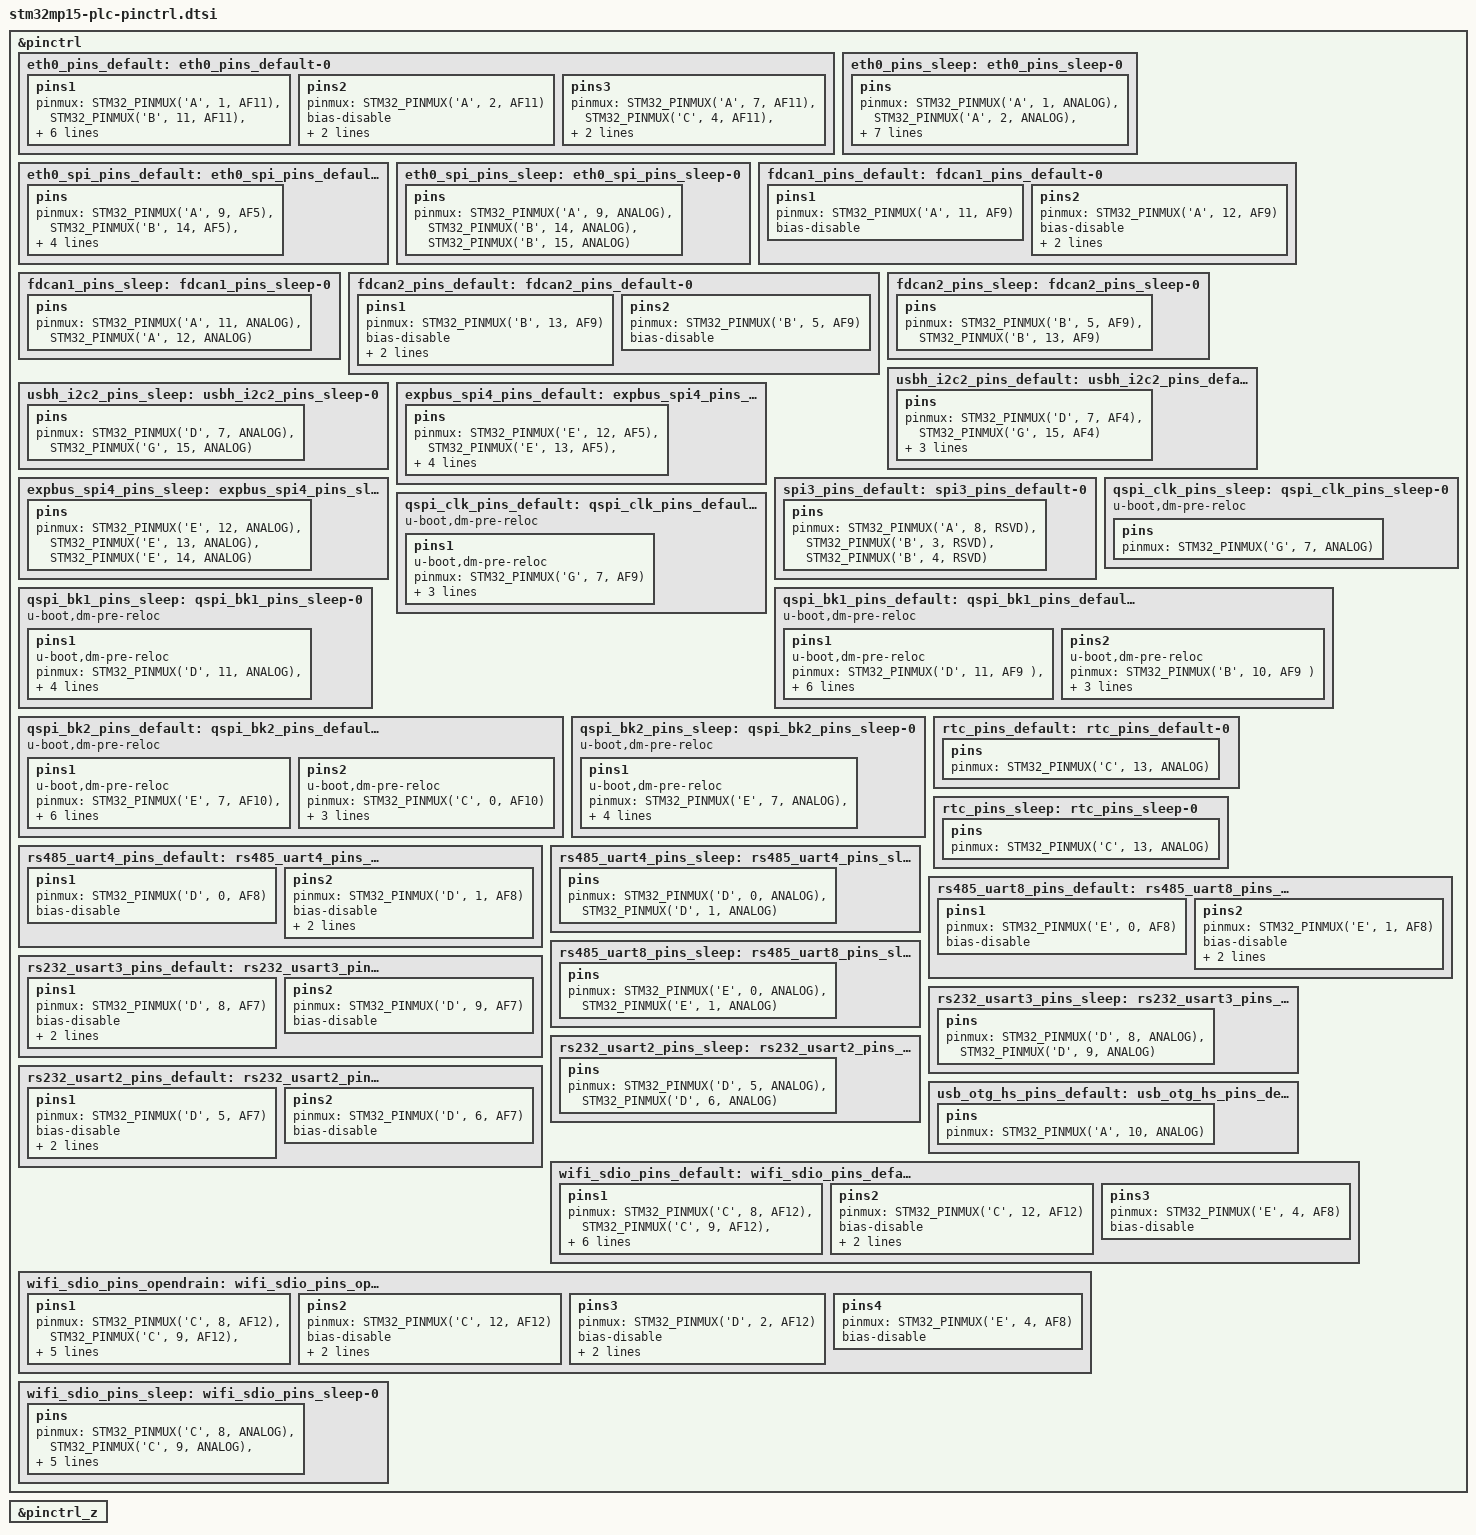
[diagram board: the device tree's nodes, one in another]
/* SPDX-License-Identifier: (GPL-2.0+ OR BSD-3-Clause) */
/*
 * Copyright (C) STMicroelectronics 2020 - All Rights Reserved
 * Author: STM32CubeMX code generation for STMicroelectronics.
 */

/* For more information on Device Tree configuration, please refer to
 * https://wiki.st.com/stm32mpu/wiki/Category:Device_tree_configuration
 */

#include <dt-bindings/pinctrl/stm32-pinfunc.h>

#include "stm32mp153.dtsi"
#include "stm32mp15xd.dtsi"
#include "stm32mp15xxab-pinctrl.dtsi"
#include "stm32mp15-m4-srm.dtsi"

&pinctrl {
/* PLC Ethernet interface pin configuration START */
	eth0_pins_default: eth0_pins_default-0 {		
		pins1 {
			pinmux = <STM32_PINMUX('A',  1, AF11)>, /* ETH1_REF_CLK */
					 <STM32_PINMUX('B', 11, AF11)>, /* ETH1_TX_EN   */
					 <STM32_PINMUX('C',  1, AF11)>, /* ETH1_MDC     */
					 <STM32_PINMUX('G', 13, AF11)>, /* ETH1_TXD0    */
					 <STM32_PINMUX('G', 14, AF11)>; /* ETH1_TXD1    */
			bias-disable;
			drive-push-pull;
			slew-rate = <1>;
		};
		pins2 {
			pinmux = <STM32_PINMUX('A',  2, AF11)>; /* ETH1_MDIO */
			bias-disable;
			drive-push-pull;
			slew-rate = <0>;
		};
		pins3 {
			pinmux = <STM32_PINMUX('A',  7, AF11)>, /* ETH1_CRS_DV */
					 <STM32_PINMUX('C',  4, AF11)>, /* ETH1_RXD0   */
					 <STM32_PINMUX('C',  5, AF11)>; /* ETH1_RXD1   */
			bias-disable;
		};
	};

	eth0_pins_sleep: eth0_pins_sleep-0 {
		pins {
			pinmux = <STM32_PINMUX('A',  1, ANALOG)>, /* ETH1_REF_CLK */
					 <STM32_PINMUX('A',  2, ANALOG)>, /* ETH1_MDIO    */
					 <STM32_PINMUX('A',  7, ANALOG)>, /* ETH1_CRS_DV  */
					 <STM32_PINMUX('B', 11, ANALOG)>, /* ETH1_TX_EN   */
					 <STM32_PINMUX('C',  1, ANALOG)>, /* ETH1_MDC     */
					 <STM32_PINMUX('C',  4, ANALOG)>, /* ETH1_RXD0    */
					 <STM32_PINMUX('C',  5, ANALOG)>, /* ETH1_RXD1    */
					 <STM32_PINMUX('G', 13, ANALOG)>, /* ETH1_TXD0    */
					 <STM32_PINMUX('G', 14, ANALOG)>; /* ETH1_TXD1    */
		};
	};

	eth0_spi_pins_default: eth0_spi_pins_default-0 {
		pins {
			pinmux = <STM32_PINMUX('A', 9, AF5)>,  /* SPI2_SCK */
					 <STM32_PINMUX('B', 14, AF5)>, /* SPI2_MISO */
					 <STM32_PINMUX('B', 15, AF5)>; /* SPI2_MOSI */
			bias-disable;
			drive-push-pull;
			slew-rate = <1>;
		};
	};
	
	eth0_spi_pins_sleep: eth0_spi_pins_sleep-0 {
		pins {
			pinmux = <STM32_PINMUX('A', 9, ANALOG)>,  /* SPI2_SCK */
					 <STM32_PINMUX('B', 14, ANALOG)>, /* SPI2_MISO */
					 <STM32_PINMUX('B', 15, ANALOG)>; /* SPI2_MOSI */
		};
	};
/* PLC Ethernet interface pin configuration END */
/* PLC CANOpen/FDCAN Port1 interface pin configuration START */
	fdcan1_pins_default: fdcan1_pins_default-0 {
		pins1 {
			pinmux = <STM32_PINMUX('A', 11, AF9)>;    /* FDCAN1_RX    */
			bias-disable;
		};
		pins2 {
			pinmux = <STM32_PINMUX('A', 12, AF9)>;    /* FDCAN1_TX    */
			bias-disable;
			drive-push-pull;
			slew-rate = <0>;
		};
	};

	fdcan1_pins_sleep: fdcan1_pins_sleep-0 {
		pins {
			pinmux = <STM32_PINMUX('A', 11, ANALOG)>, /* FDCAN1_RX    */
					 <STM32_PINMUX('A', 12, ANALOG)>; /* FDCAN1_TX    */
		};
	};
/* PLC CANOpen/FDCAN Port1 interface pin configuration END   */
/* PLC CANOpen/FDCAN Port2 interface pin configuration START */
	fdcan2_pins_default: fdcan2_pins_default-0 {
		pins1 {
			pinmux = <STM32_PINMUX('B', 13, AF9)>;    /* FDCAN2_TX    */
			bias-disable;
			drive-push-pull;
			slew-rate = <0>;
		};
		pins2 {
			pinmux = <STM32_PINMUX('B',  5, AF9)>;    /* FDCAN2_RX    */
			bias-disable;
		};
	};
	
	fdcan2_pins_sleep: fdcan2_pins_sleep-0 {
		pins {
			pinmux = <STM32_PINMUX('B',  5, AF9)>,    /* FDCAN2_RX    */
					 <STM32_PINMUX('B', 13, AF9)>;    /* FDCAN2_TX    */
		};
	};
/* PLC CANOpen/FDCAN Port2 interface pin configuration END   */
/* PLC USB Hub Controller I2C2 interface pin configuration START */
	usbh_i2c2_pins_default: usbh_i2c2_pins_default-0 {
		pins {
			pinmux = <STM32_PINMUX('D',  7, AF4)>,    /* I2C2_SCL     */
					 <STM32_PINMUX('G', 15, AF4)>;    /* I2C2_SDA     */
			bias-disable;
			drive-open-drain;
			slew-rate = <0>;
		};
	};

	usbh_i2c2_pins_sleep: usbh_i2c2_pins_sleep-0 {
		pins {
			pinmux = <STM32_PINMUX('D',  7, ANALOG)>, /* I2C2_SCL    */
					 <STM32_PINMUX('G', 15, ANALOG)>; /* I2C2_SDA    */
		};
	};
/* PLC USB Hub Controller I2C2 interface pin configuration END */
/* PLC Expansion Modules SPI4 interface pin configuration START */
	expbus_spi4_pins_default: expbus_spi4_pins_default-0 {
		pins {
			pinmux = <STM32_PINMUX('E', 12, AF5)>, /* SPI4_SCK */
					 <STM32_PINMUX('E', 13, AF5)>, /* SPI4_MISO */
					 <STM32_PINMUX('E', 14, AF5)>; /* SPI4_MOSI */
			bias-disable;
			drive-push-pull;
			slew-rate = <1>;
		};
	};
	expbus_spi4_pins_sleep: expbus_spi4_pins_sleep-0 {
		pins {
			pinmux = <STM32_PINMUX('E', 12, ANALOG)>, /* SPI4_SCK */
					 <STM32_PINMUX('E', 13, ANALOG)>, /* SPI4_MISO */
					 <STM32_PINMUX('E', 14, ANALOG)>; /* SPI4_MOSI */
		};
	};
/* PLC Expansion Modules SPI4 interface pin configuration END */
/* PLC Flash's QuadSPI interface pin configuration START */
	spi3_pins_default: spi3_pins_default-0 {
		pins {
			pinmux = <STM32_PINMUX('A',  8, RSVD)>,   /* SPI3_MOSI   */
					 <STM32_PINMUX('B',  3, RSVD)>,   /* SPI3_SCK    */
					 <STM32_PINMUX('B',  4, RSVD)>;   /* SPI3_MISO   */
		};
	};

	qspi_clk_pins_default: qspi_clk_pins_default-0 {
		u-boot,dm-pre-reloc;
		pins1 {
			u-boot,dm-pre-reloc;
			pinmux = <STM32_PINMUX('G', 7, AF9)>; 	/* QUADSPI_CLK */
			bias-disable;
			drive-push-pull;
			slew-rate = <3>;
		};
	};
	qspi_clk_pins_sleep: qspi_clk_pins_sleep-0 {		
		u-boot,dm-pre-reloc;
		pins {
			pinmux = <STM32_PINMUX('G', 7, ANALOG)>; /* QSPI_CLK */
		};
	};
	qspi_bk1_pins_default: qspi_bk1_pins_default-0 {	/* PLC QuadSPI BK1 W25N02K pin configuration */
		u-boot,dm-pre-reloc;
		pins1 {
			u-boot,dm-pre-reloc;
			pinmux = <STM32_PINMUX('D', 11, AF9 )>, /* QUADSPI_BK1_IO0 */
					 <STM32_PINMUX('F',  9, AF10)>, /* QUADSPI_BK1_IO1 */
					 <STM32_PINMUX('F',  7, AF9 )>, /* QUADSPI_BK1_IO2 */
					 <STM32_PINMUX('F',  6, AF9 )>; /* QUADSPI_BK1_IO3 */
			bias-disable;
			drive-push-pull;
			slew-rate = <2>;
		};
		pins2 {
			u-boot,dm-pre-reloc;
			pinmux = <STM32_PINMUX('B', 10, AF9 )>; /* QUADSPI_BK1_NCS */
			bias-pull-up;
			drive-push-pull;
			slew-rate = <1>;
		};
	};
	qspi_bk1_pins_sleep: qspi_bk1_pins_sleep-0 {
		u-boot,dm-pre-reloc;
		pins1 {
			u-boot,dm-pre-reloc;
			pinmux = <STM32_PINMUX('D', 11, ANALOG)>, /* QUADSPI_BK1_IO0 */
					 <STM32_PINMUX('F',  9, ANALOG)>, /* QUADSPI_BK1_IO1 */
					 <STM32_PINMUX('F',  7, ANALOG)>, /* QUADSPI_BK1_IO2 */
					 <STM32_PINMUX('F',  6, ANALOG)>, /* QUADSPI_BK1_IO3 */
					 <STM32_PINMUX('B', 10, ANALOG)>; /* QUADSPI_BK1_NCS */
		};
	};
	qspi_bk2_pins_default: qspi_bk2_pins_default-0 {	/* PLC QuadSPI BK2 W25Q128JV pin configuration */
		u-boot,dm-pre-reloc;
		pins1 {
			u-boot,dm-pre-reloc;
			pinmux = <STM32_PINMUX('E',  7, AF10)>, /* QUADSPI_BK2_IO0 */
					 <STM32_PINMUX('E',  8, AF10)>, /* QUADSPI_BK2_IO1 */
					 <STM32_PINMUX('G', 10, AF11)>, /* QUADSPI_BK2_IO2 */
					 <STM32_PINMUX('E', 10, AF10)>; /* QUADSPI_BK2_IO3 */
			bias-disable;
			drive-push-pull;
			slew-rate = <2>;
		};
		pins2 {
			u-boot,dm-pre-reloc;
			pinmux = <STM32_PINMUX('C',  0, AF10)>; /* QUADSPI_BK2_NCS */
			bias-pull-up;
			drive-push-pull;
			slew-rate = <1>;
		};
	};
	qspi_bk2_pins_sleep: qspi_bk2_pins_sleep-0 {
		u-boot,dm-pre-reloc;
		pins1 {
			u-boot,dm-pre-reloc;
			pinmux = <STM32_PINMUX('E',  7, ANALOG)>, /* QUADSPI_BK2_IO0 */
					 <STM32_PINMUX('E',  8, ANALOG)>, /* QUADSPI_BK2_IO1 */
					 <STM32_PINMUX('G', 10, ANALOG)>, /* QUADSPI_BK2_IO2 */
					 <STM32_PINMUX('E', 10, ANALOG)>, /* QUADSPI_BK2_IO3 */
					 <STM32_PINMUX('C',  0, ANALOG)>; /* QUADSPI_BK2_NCS */
		};
	};
/* PLC Flash's QuadSPI interface pin configuration END */
/* PLC RTC interface pin configuration START */
	rtc_pins_default: rtc_pins_default-0 {
		pins {
			pinmux = <STM32_PINMUX('C', 13, ANALOG)>; /* RTC_LSCO */
		};
	};
	rtc_pins_sleep: rtc_pins_sleep-0 {
		pins {
			pinmux = <STM32_PINMUX('C', 13, ANALOG)>; /* RTC_LSCO */
		};
	};
/* PLC RTC interface pin configuration END */
/* PLC RS485 Port1 UART4 interface pin configuration START */
	rs485_uart4_pins_default: rs485_uart4_pins_default-0 {
		pins1 {
			pinmux = <STM32_PINMUX('D', 0, AF8)>; /* UART4_RX */
			bias-disable;
		};
		pins2 {
			pinmux = <STM32_PINMUX('D', 1, AF8)>; /* UART4_TX */
			bias-disable;
			drive-push-pull;
			slew-rate = <0>;
		};
	};
	rs485_uart4_pins_sleep: rs485_uart4_pins_sleep-0 {
		pins {
			pinmux = <STM32_PINMUX('D', 0, ANALOG)>, /* UART4_RX */
					 <STM32_PINMUX('D', 1, ANALOG)>; /* UART4_TX */
		};
	};
/* PLC RS485 Port1 UART4 interface pin configuration END   */
/* PLC RS485 Port2 UART8 interface pin configuration START */
	rs485_uart8_pins_default: rs485_uart8_pins_default-0 {
		pins1 {
			pinmux = <STM32_PINMUX('E', 0, AF8)>; /* UART8_RX */
			bias-disable;
		};
		pins2 {
			pinmux = <STM32_PINMUX('E', 1, AF8)>; /* UART8_TX */
			bias-disable;
			drive-push-pull;
			slew-rate = <0>;
		};
	};
	rs485_uart8_pins_sleep: rs485_uart8_pins_sleep-0 {
		pins {
			pinmux = <STM32_PINMUX('E', 0, ANALOG)>, /* UART8_RX */
					 <STM32_PINMUX('E', 1, ANALOG)>; /* UART8_TX */
		};
	};
/* PLC RS485 Port2 UART8 interface pin configuration END   */
/* PLC RS232 Port1 USART3 interface pin configuration START */
	rs232_usart3_pins_default: rs232_usart3_pins_default-0 {
		pins1 {
			pinmux = <STM32_PINMUX('D', 8, AF7)>; /* USART3_TX */
			bias-disable;
			drive-push-pull;
			slew-rate = <0>;
		};
		pins2 {
			pinmux = <STM32_PINMUX('D', 9, AF7)>; /* USART3_RX */
			bias-disable;
		};
	};
	rs232_usart3_pins_sleep: rs232_usart3_pins_sleep-0 {
		pins {
			pinmux = <STM32_PINMUX('D', 8, ANALOG)>, /* USART3_TX */
					 <STM32_PINMUX('D', 9, ANALOG)>; /* USART3_RX */
		};
	};
/* PLC RS232 Port1 USART3 interface pin configuration END */
/* PLC RS232 Port2 USART2 interface pin configuration START */
	rs232_usart2_pins_default: rs232_usart2_pins_default-0 {
		pins1 {
			pinmux = <STM32_PINMUX('D', 5, AF7)>; /* USART2_TX */
			bias-disable;
			drive-push-pull;
			slew-rate = <0>;
		};
		pins2 {
			pinmux = <STM32_PINMUX('D', 6, AF7)>; /* USART2_RX */
			bias-disable;
		};
	};
	rs232_usart2_pins_sleep: rs232_usart2_pins_sleep-0 {
		pins {
			pinmux = <STM32_PINMUX('D', 5, ANALOG)>, /* USART2_TX */
					 <STM32_PINMUX('D', 6, ANALOG)>; /* USART2_RX */
		};
	};
/* PLC RS232 Port2 USART2 interface pin configuration END */

	usb_otg_hs_pins_default: usb_otg_hs_pins_default-0 {
		pins {
			pinmux = <STM32_PINMUX('A', 10, ANALOG)>; /* USB_OTG_HS_ID */
		};
	};

/* PLC Lily-W1 WiFi module SDIO pin configuration START */
	wifi_sdio_pins_default: wifi_sdio_pins_default-0 {
		pins1 {
			pinmux = <STM32_PINMUX('C',  8, AF12)>, /* SDMMC1_D0  */
					 <STM32_PINMUX('C',  9, AF12)>, /* SDMMC1_D1  */
					 <STM32_PINMUX('C', 10, AF12)>, /* SDMMC1_D2  */
					 <STM32_PINMUX('C', 11, AF12)>, /* SDMMC1_D3  */
					 <STM32_PINMUX('D',  2, AF12)>; /* SDMMC1_CMD */
			bias-disable;
			drive-push-pull;
			slew-rate = <1>;
		};
		pins2 {
			pinmux = <STM32_PINMUX('C', 12, AF12)>; /* SDMMC1_CK */
			bias-disable;
			drive-push-pull;
			slew-rate = <3>;
		};
		pins3 {
			pinmux = <STM32_PINMUX('E', 4, AF8)>; /* SDMMC1_CKIN */
			bias-disable;
		};
	};

	wifi_sdio_pins_opendrain: wifi_sdio_pins_opendrain-0 {
		pins1 {
			pinmux = <STM32_PINMUX('C', 8, AF12)>, /* SDMMC1_D0 */
					 <STM32_PINMUX('C', 9, AF12)>, /* SDMMC1_D1 */
					 <STM32_PINMUX('C', 10, AF12)>, /* SDMMC1_D2 */
					 <STM32_PINMUX('C', 11, AF12)>; /* SDMMC1_D3 */
			bias-disable;
			drive-push-pull;
			slew-rate = <1>;
		};
		pins2 {
			pinmux = <STM32_PINMUX('C', 12, AF12)>; /* SDMMC1_CK */
			bias-disable;
			drive-push-pull;
			slew-rate = <3>;
		};
		pins3 {
			pinmux = <STM32_PINMUX('D', 2, AF12)>; /* SDMMC1_CMD */
			bias-disable;
			drive-open-drain;
			slew-rate = <1>;
		};
		pins4 {
			pinmux = <STM32_PINMUX('E', 4, AF8)>; /* SDMMC1_CKIN */
			bias-disable;
		};
	};

	wifi_sdio_pins_sleep: wifi_sdio_pins_sleep-0 {
		pins {
			pinmux = <STM32_PINMUX('C', 8, ANALOG)>, /* SDMMC1_D0 */
					 <STM32_PINMUX('C', 9, ANALOG)>, /* SDMMC1_D1 */
					 <STM32_PINMUX('C', 10, ANALOG)>, /* SDMMC1_D2 */
					 <STM32_PINMUX('C', 11, ANALOG)>, /* SDMMC1_D3 */
					 <STM32_PINMUX('C', 12, ANALOG)>, /* SDMMC1_CK */
					 <STM32_PINMUX('D', 2, ANALOG)>, /* SDMMC1_CMD */
					 <STM32_PINMUX('E', 4, ANALOG)>; /* SDMMC1_CKIN */
		};
	};
/* PLC Lily-W1 WiFi module SDIO pin configuration END */
};

&pinctrl_z {

};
